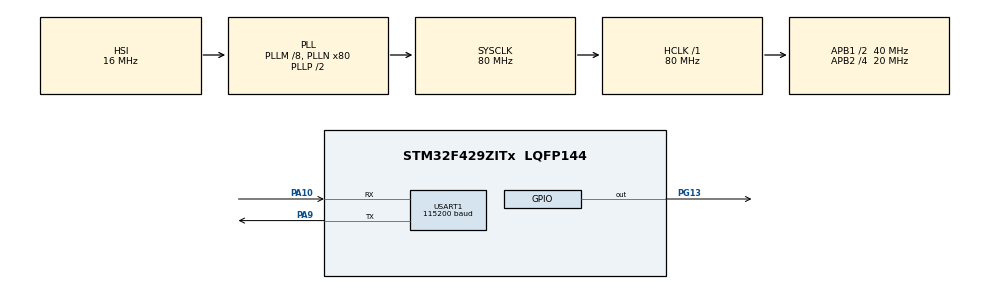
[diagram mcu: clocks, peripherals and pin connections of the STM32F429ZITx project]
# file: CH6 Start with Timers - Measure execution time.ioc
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Mcu.Family=STM32F4
Mcu.Name=STM32F429ZITx
Mcu.Package=LQFP144
NVIC.PriorityGroup=NVIC_PRIORITYGROUP_0
PA10.Mode=Asynchronous
PA10.Signal=USART1_RX
PA9.Mode=Asynchronous
PA9.Signal=USART1_TX
PG13.Signal=GPIO_Output
ProjectManager.HeapSize=0x200
ProjectManager.StackSize=0x400
ProjectManager.TargetToolchain=STM32CubeIDE
RCC.48MHZClocksFreq_Value=22857142.85714286
RCC.AHBFreq_Value=80000000
RCC.APB1CLKDivider=RCC_HCLK_DIV2
RCC.APB1Freq_Value=40000000
RCC.APB1TimFreq_Value=80000000
RCC.APB2CLKDivider=RCC_HCLK_DIV4
RCC.APB2Freq_Value=20000000
RCC.APB2TimFreq_Value=40000000
RCC.CortexFreq_Value=80000000
RCC.HCLKFreq_Value=80000000
RCC.HSE_VALUE=8000000
RCC.HSI_VALUE=16000000
RCC.LSE_VALUE=32768
RCC.PLLM=8
RCC.PLLN=80
RCC.PLLQ=7
RCC.SYSCLKFreq_VALUE=80000000
RCC.SYSCLKSource=RCC_SYSCLKSOURCE_PLLCLK
RCC.VCOOutputFreq_Value=160000000
TIM1.Period=65535-1
TIM1.Prescaler=40-1
USART1.BaudRate=115200
USART1.OverSampling=UART_OVERSAMPLING_8
USART1.VirtualMode=VM_ASYNC
VP_TIM1_VS_ClockSourceINT.Mode=Internal
board=STM32F429I-DISC1

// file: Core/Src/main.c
/* USER CODE BEGIN Header */
/**
  ******************************************************************************
  * @file           : main.c
  * @brief          : Main program body
  ******************************************************************************
  * @attention
  *
  * Copyright (c) 2023 STMicroelectronics.
  * All rights reserved.
  *
  * This software is licensed under terms that can be found in the LICENSE file
  * in the root directory of this software component.
  * If no LICENSE file comes with this software, it is provided AS-IS.
  *
  ******************************************************************************
  */
/* USER CODE END Header */
#include "main.h"

/* USER CODE BEGIN Includes */

#include <stdio.h>

/* USER CODE END Includes */

TIM_HandleTypeDef htim1;

UART_HandleTypeDef huart1;

/* USER CODE BEGIN PV */

char uart_buf[80];
uint32_t uart_buf_len;
uint16_t timer_val;

/* USER CODE END PV */

void SystemClock_Config(void);
static void MX_GPIO_Init(void);
static void MX_TIM1_Init(void);
static void MX_USART1_UART_Init(void);

int main(void)
{

  /* MCU Configuration--------------------------------------------------------*/

  /* Reset of all peripherals, Initializes the Flash interface and the Systick. */
  HAL_Init();

  /* Configure the system clock */
  SystemClock_Config();

  /* Initialize all configured peripherals */
  MX_GPIO_Init();
  MX_TIM1_Init();
  MX_USART1_UART_Init();
  /* USER CODE BEGIN 2 */
  uart_buf_len = sprintf(uart_buf, "Test started!\r\n");
  HAL_UART_Transmit(&huart1, (const uint8_t*)uart_buf, uart_buf_len, HAL_MAX_DELAY);

  // Start timer
  HAL_TIM_Base_Start(&htim1);

  /* USER CODE END 2 */

  /* Infinite loop */
  /* USER CODE BEGIN WHILE */
  while (1)
  {

	  // Example code to measure execution time
	  // Get current time value
  	  timer_val = __HAL_TIM_GetCounter(&htim1);
  	  // toggle pin and wait 500 ms
  	  HAL_GPIO_TogglePin(GPIOG, GPIO_PIN_13);
  	  HAL_Delay(50);
  	  timer_val = __HAL_TIM_GetCounter(&htim1) - timer_val;

	  // Show elapsed time
	  uart_buf_len = sprintf(uart_buf, "Elapsed time: %u us\r\n", timer_val);
	  HAL_UART_Transmit(&huart1, (const uint8_t*) uart_buf, uart_buf_len, HAL_MAX_DELAY);

	  HAL_Delay(1000);

    /* USER CODE END WHILE */

  }
}

void SystemClock_Config(void)
{
  RCC_OscInitTypeDef RCC_OscInitStruct = {0};
  RCC_ClkInitTypeDef RCC_ClkInitStruct = {0};

  /** Configure the main internal regulator output voltage
  */
  __HAL_RCC_PWR_CLK_ENABLE();
  __HAL_PWR_VOLTAGESCALING_CONFIG(PWR_REGULATOR_VOLTAGE_SCALE3);

  /** Initializes the RCC Oscillators according to the specified parameters
  * in the RCC_OscInitTypeDef structure.
  */
  RCC_OscInitStruct.OscillatorType = RCC_OSCILLATORTYPE_HSI;
  RCC_OscInitStruct.HSIState = RCC_HSI_ON;
  RCC_OscInitStruct.HSICalibrationValue = RCC_HSICALIBRATION_DEFAULT;
  RCC_OscInitStruct.PLL.PLLState = RCC_PLL_ON;
  RCC_OscInitStruct.PLL.PLLSource = RCC_PLLSOURCE_HSI;
  RCC_OscInitStruct.PLL.PLLM = 8;
  RCC_OscInitStruct.PLL.PLLN = 80;
  RCC_OscInitStruct.PLL.PLLP = RCC_PLLP_DIV2;
  RCC_OscInitStruct.PLL.PLLQ = 7;
  if (HAL_RCC_OscConfig(&RCC_OscInitStruct) != HAL_OK)
  {
    Error_Handler();
  }

  /** Initializes the CPU, AHB and APB buses clocks
  */
  RCC_ClkInitStruct.ClockType = RCC_CLOCKTYPE_HCLK|RCC_CLOCKTYPE_SYSCLK
                              |RCC_CLOCKTYPE_PCLK1|RCC_CLOCKTYPE_PCLK2;
  RCC_ClkInitStruct.SYSCLKSource = RCC_SYSCLKSOURCE_PLLCLK;
  RCC_ClkInitStruct.AHBCLKDivider = RCC_SYSCLK_DIV1;
  RCC_ClkInitStruct.APB1CLKDivider = RCC_HCLK_DIV2;
  RCC_ClkInitStruct.APB2CLKDivider = RCC_HCLK_DIV4;

  if (HAL_RCC_ClockConfig(&RCC_ClkInitStruct, FLASH_LATENCY_2) != HAL_OK)
  {
    Error_Handler();
  }
}

static void MX_TIM1_Init(void)
{

  TIM_ClockConfigTypeDef sClockSourceConfig = {0};
  TIM_MasterConfigTypeDef sMasterConfig = {0};

  htim1.Instance = TIM1;
  htim1.Init.Prescaler = 40-1;
  htim1.Init.CounterMode = TIM_COUNTERMODE_UP;
  htim1.Init.Period = 65535-1;
  htim1.Init.ClockDivision = TIM_CLOCKDIVISION_DIV1;
  htim1.Init.RepetitionCounter = 0;
  htim1.Init.AutoReloadPreload = TIM_AUTORELOAD_PRELOAD_DISABLE;
  if (HAL_TIM_Base_Init(&htim1) != HAL_OK)
  {
    Error_Handler();
  }
  sClockSourceConfig.ClockSource = TIM_CLOCKSOURCE_INTERNAL;
  if (HAL_TIM_ConfigClockSource(&htim1, &sClockSourceConfig) != HAL_OK)
  {
    Error_Handler();
  }
  sMasterConfig.MasterOutputTrigger = TIM_TRGO_RESET;
  sMasterConfig.MasterSlaveMode = TIM_MASTERSLAVEMODE_DISABLE;
  if (HAL_TIMEx_MasterConfigSynchronization(&htim1, &sMasterConfig) != HAL_OK)
  {
    Error_Handler();
  }

}

static void MX_USART1_UART_Init(void)
{

  huart1.Instance = USART1;
  huart1.Init.BaudRate = 115200;
  huart1.Init.WordLength = UART_WORDLENGTH_8B;
  huart1.Init.StopBits = UART_STOPBITS_1;
  huart1.Init.Parity = UART_PARITY_NONE;
  huart1.Init.Mode = UART_MODE_TX_RX;
  huart1.Init.HwFlowCtl = UART_HWCONTROL_NONE;
  huart1.Init.OverSampling = UART_OVERSAMPLING_8;
  if (HAL_UART_Init(&huart1) != HAL_OK)
  {
    Error_Handler();
  }

}

static void MX_GPIO_Init(void)
{
  GPIO_InitTypeDef GPIO_InitStruct = {0};

  /* GPIO Ports Clock Enable */
  __HAL_RCC_GPIOA_CLK_ENABLE();
  __HAL_RCC_GPIOG_CLK_ENABLE();

  /*Configure GPIO pin Output Level */
  HAL_GPIO_WritePin(GPIOG, GPIO_PIN_13, GPIO_PIN_RESET);

  /*Configure GPIO pin : PG13 */
  GPIO_InitStruct.Pin = GPIO_PIN_13;
  GPIO_InitStruct.Mode = GPIO_MODE_OUTPUT_PP;
  GPIO_InitStruct.Pull = GPIO_NOPULL;
  GPIO_InitStruct.Speed = GPIO_SPEED_FREQ_LOW;
  HAL_GPIO_Init(GPIOG, &GPIO_InitStruct);

}

void Error_Handler(void)
{
  __disable_irq();
  while (1)
  {
  }
}
